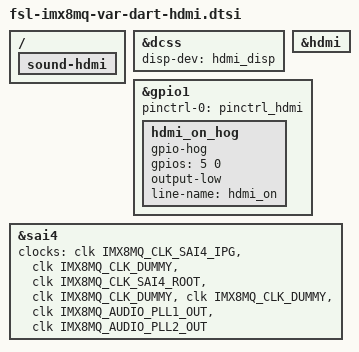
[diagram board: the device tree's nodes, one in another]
/*
 * Copyright 2017 NXP
 * Copyright 2018-2019 Variscite Ltd.
 *
 * This program is free software; you can redistribute it and/or
 * modify it under the terms of the GNU General Public License
 * as published by the Free Software Foundation; either version 2
 * of the License, or (at your option) any later version.
 *
 * This program is distributed in the hope that it will be useful,
 * but WITHOUT ANY WARRANTY; without even the implied warranty of
 * MERCHANTABILITY or FITNESS FOR A PARTICULAR PURPOSE.  See the
 * GNU General Public License for more details.
 */

/ {
	sound-hdmi {
		status = "okay";
	};
};

&dcss {
	status = "okay";
	disp-dev = "hdmi_disp";
};

&hdmi {
	status = "okay";
};

&gpio1 {
	pinctrl-names = "default";
	pinctrl-0 = <&pinctrl_hdmi>;

	hdmi_on_hog {
		gpio-hog;
		gpios = <5 0>;
		output-low;
		line-name = "hdmi_on";
	};
};

&sai4 {
	clocks = <&clk IMX8MQ_CLK_SAI4_IPG>, <&clk IMX8MQ_CLK_DUMMY>,
		<&clk IMX8MQ_CLK_SAI4_ROOT>, <&clk IMX8MQ_CLK_DUMMY>,
		<&clk IMX8MQ_CLK_DUMMY>, <&clk IMX8MQ_AUDIO_PLL1_OUT>,
		<&clk IMX8MQ_AUDIO_PLL2_OUT>;
	clock-names = "bus", "mclk0", "mclk1", "mclk2", "mclk3", "pll8k", "pll11k";
	status = "okay";
};
